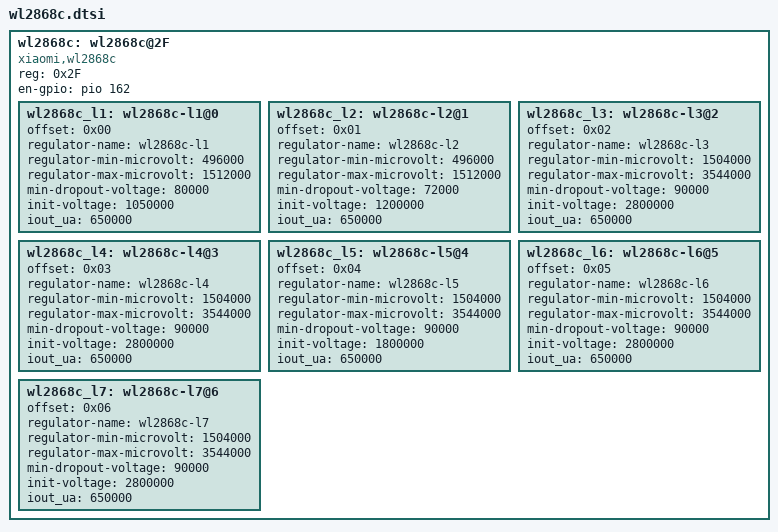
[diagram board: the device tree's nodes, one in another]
wl2868c: wl2868c@2F {
	compatible = "xiaomi,wl2868c";
	reg = <0x2F>;/*slave address*/
	en-gpio = <&pio 162 0x0>;

	wl2868c_l1:wl2868c-l1@0{
		offset = /bits/ 16 <0x00>;
		regulator-name ="wl2868c-l1";
		regulator-min-microvolt = <496000>;
		regulator-max-microvolt = <1512000>;
		min-dropout-voltage = <80000>;
		init-voltage = <1050000>;
		iout_ua = <650000>;
	};

	wl2868c_l2:wl2868c-l2@1{
		offset = /bits/ 16 <0x01>;
		regulator-name ="wl2868c-l2";
		regulator-min-microvolt = <496000>;
		regulator-max-microvolt = <1512000>;
		min-dropout-voltage = <72000>;
		init-voltage = <1200000>;
		iout_ua = <650000>;
	};

	wl2868c_l3:wl2868c-l3@2{
		offset = /bits/ 16 <0x02>;
		regulator-name ="wl2868c-l3";
		regulator-min-microvolt = <1504000>;
		regulator-max-microvolt = <3544000>;
		min-dropout-voltage = <90000>;
		init-voltage = <2800000>;
		iout_ua = <650000>;
	};

	wl2868c_l4:wl2868c-l4@3{
		offset = /bits/ 16 <0x03>;
		regulator-name ="wl2868c-l4";
		regulator-min-microvolt = <1504000>;
		regulator-max-microvolt = <3544000>;
		min-dropout-voltage = <90000>;
		init-voltage = <2800000>;
		iout_ua = <650000>;
	};

	wl2868c_l5:wl2868c-l5@4{
		offset = /bits/ 16 <0x04>;
		regulator-name ="wl2868c-l5";
		regulator-min-microvolt = <1504000>;
		regulator-max-microvolt = <3544000>;
		min-dropout-voltage = <90000>;
		init-voltage = <1800000>;
		iout_ua = <650000>;
	};

	wl2868c_l6:wl2868c-l6@5{
		offset = /bits/ 16 <0x05>;
		regulator-name ="wl2868c-l6";
		regulator-min-microvolt = <1504000>;
		regulator-max-microvolt = <3544000>;
		min-dropout-voltage = <90000>;
		init-voltage = <2800000>;
		iout_ua = <650000>;
	};

	wl2868c_l7:wl2868c-l7@6{
		offset = /bits/ 16 <0x06>;
		regulator-name ="wl2868c-l7";
		regulator-min-microvolt = <1504000>;
		regulator-max-microvolt = <3544000>;
		min-dropout-voltage = <90000>;
		init-voltage = <2800000>;
		iout_ua = <650000>;
	};
};
